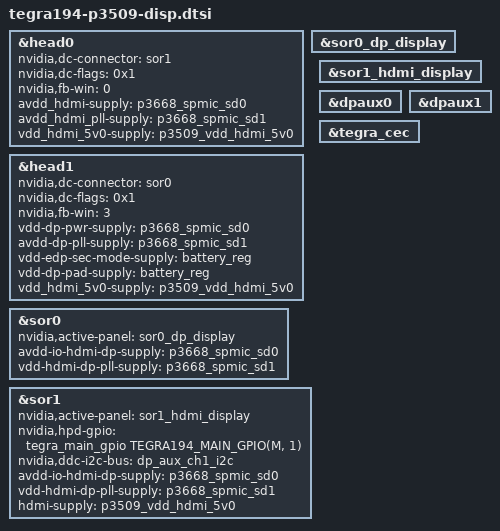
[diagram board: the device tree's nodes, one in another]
/*
 * tegra194-p3509-disp.dtsi:
 *
 * Copyright (c) 2019, NVIDIA CORPORATION.  All rights reserved.
 *
 * This program is free software; you can redistribute it and/or modify
 * it under the terms of the GNU General Public License as published by
 * the Free Software Foundation; version 2 of the License.
 *
 * This program is distributed in the hope that it will be useful, but WITHOUT
 * ANY WARRANTY; without even the implied warranty of MERCHANTABILITY or
 * FITNESS FOR A PARTICULAR PURPOSE.  See the GNU General Public License for
 * more details.
 *
 *
 * t194 jakku product uses 2 display heads out of the 4 available on t194:
 *	fb0: Head0->SOR1->HDMI
 *	fb1: Head1->SOR0->DP
 * Each display head is assigned three windows each.
 */

#include "tegra194-fixed-regulator-p3509-0000-a00.dtsi"
#include "tegra194-spmic-p3668.dtsi"

&head0 {
	status = "okay";
	nvidia,dc-connector = <&sor1>; // nvdisp-init only
	nvidia,dc-flags = <0x1>; // nvdisp-init only
	nvidia,fb-win = <0>; // nvdisp-init only
	avdd_hdmi-supply = <&p3668_spmic_sd0>; /* 1v0 */ // nvdisp-init only
	avdd_hdmi_pll-supply = <&p3668_spmic_sd1>; /* 1v8 */ // nvdisp-init only
	vdd_hdmi_5v0-supply = <&p3509_vdd_hdmi_5v0>; /* 5v0 */ // nvdisp-init only
};

&head1 {
	status = "okay";
	nvidia,dc-connector = <&sor0>; // nvdisp-init only
	nvidia,dc-flags = <0x1>; // nvdisp-init only
	nvidia,fb-win = <3>; // nvdisp-init only
	vdd-dp-pwr-supply = <&p3668_spmic_sd0>; // nvdisp-init only
	avdd-dp-pll-supply = <&p3668_spmic_sd1>; // nvdisp-init only
	vdd-edp-sec-mode-supply = <&battery_reg>; // nvdisp-init only
	vdd-dp-pad-supply = <&battery_reg>; // nvdisp-init only
	vdd_hdmi_5v0-supply = <&p3509_vdd_hdmi_5v0>; // nvdisp-init only
};

&sor0 {
	status = "okay";
	nvidia,active-panel = <&sor0_dp_display>;
	avdd-io-hdmi-dp-supply  = <&p3668_spmic_sd0>;
	vdd-hdmi-dp-pll-supply = <&p3668_spmic_sd1>;
};

&sor0_dp_display {
	status = "okay";
};

&sor1 {
	status = "okay";
	nvidia,active-panel = <&sor1_hdmi_display>;
	nvidia,hpd-gpio = <&tegra_main_gpio TEGRA194_MAIN_GPIO(M, 1) GPIO_ACTIVE_HIGH>;
	nvidia,ddc-i2c-bus = <&dp_aux_ch1_i2c>;
	avdd-io-hdmi-dp-supply = <&p3668_spmic_sd0>; /* 1v0 */
	vdd-hdmi-dp-pll-supply = <&p3668_spmic_sd1>; /* 1v8 */
	hdmi-supply = <&p3509_vdd_hdmi_5v0>; /* 5v0 */
};

&sor1_hdmi_display {
	status = "okay";
};

&dpaux0 {
	status = "okay";
};

&dpaux1 {
	status = "okay";
};

&tegra_cec {
	status = "okay";
};
